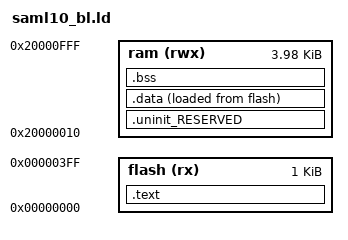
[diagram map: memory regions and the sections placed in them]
/**
*
* \brief GCC linker script (flash) for ATSAML10 family
*
* Copyright (c) 2018 Microchip Technology Inc.
*
* SPDX-License-Identifier: Apache-2.0
*
* Licensed under the Apache License, Version 2.0 (the "License"); you may
* not use this file except in compliance with the License.
* You may obtain a copy of the Licence at
*
 * http://www.apache.org/licenses/LICENSE-2.0
*
 * Unless required by applicable law or agreed to in writing, software
* distributed under the License is distributed on an AS IS BASIS, WITHOUT
* WARRANTIES OR CONDITIONS OF ANY KIND, either express or implied.
* See the License for the specific language governing permissions and
* limitations under the License.
*
*/

MEMORY
{
  flash (rx)  : ORIGIN = 0x00000000, LENGTH = 1K
  ram   (rwx) : ORIGIN = 0x20000010, LENGTH = 4096 - 16
}

__top_ram = ORIGIN(ram) + LENGTH(ram);

ENTRY(irq_handler_reset)

SECTIONS
{
  .text : ALIGN(4)
  {
    FILL(0xff)
    KEEP(*(.vectors))
    *(.romfunc)
    *(.romfunc.*)
    . = ALIGN(4);
  } > flash

  . = ALIGN(4);
  _etext = .;

  .uninit_RESERVED : ALIGN(4)
  {
    KEEP(*(.bss.$RESERVED*))
  } > ram

  .data : ALIGN(4)
  {
    FILL(0xff)
    _data = .;
    *(.ram_vectors)
    *(.text*)
    *(.rodata)
    *(.rodata.*)
    *(vtable)
    *(.data*)
    . = ALIGN(4);
    _edata = .;
  } > ram AT > flash

  .bss : ALIGN(4)
  {
    _bss = .;
    *(.bss*)
    *(COMMON)
    . = ALIGN(4);
    _ebss = .;
    PROVIDE(_end = .);
  } > ram

  PROVIDE(_stack_top = __top_ram - 0);
}
